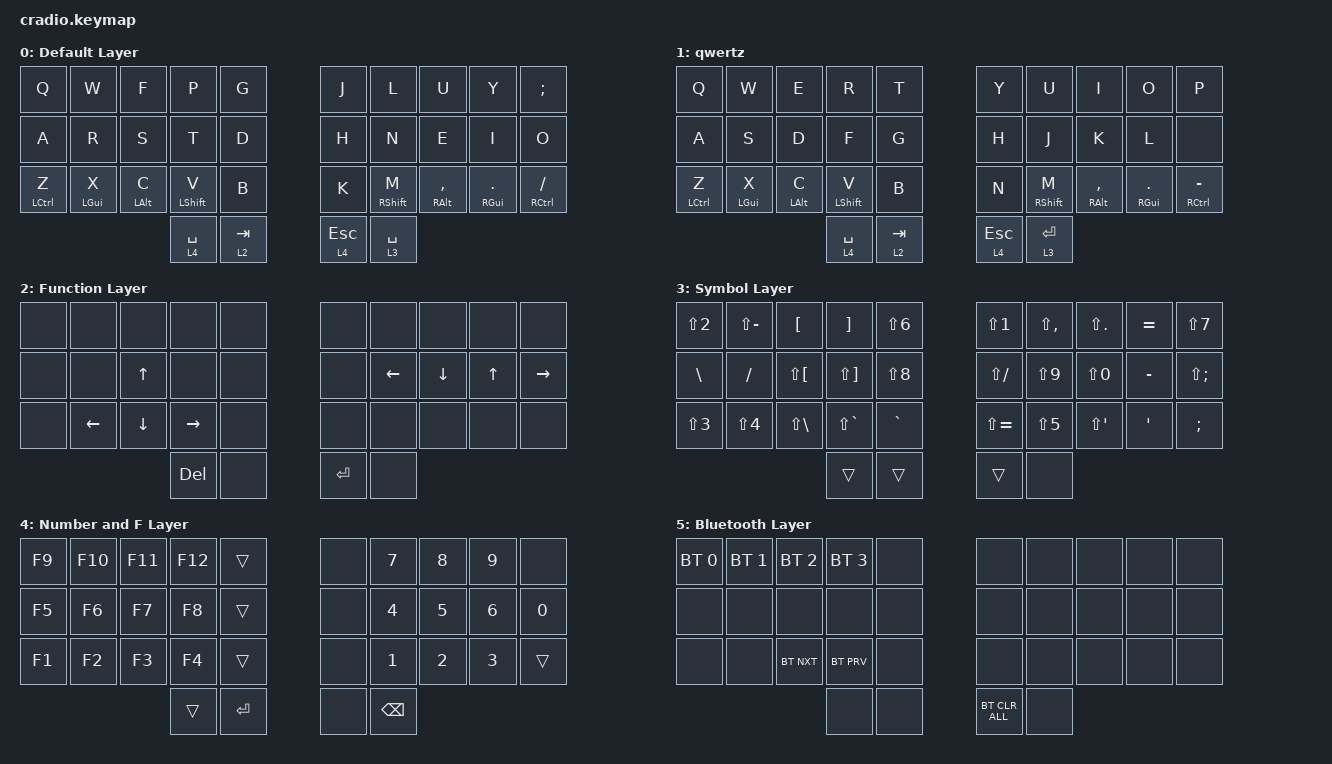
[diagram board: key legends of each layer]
// Copyright (c) 2022 The ZMK Contributors
// SPDX-License-Identifier: MIT

#include <behaviors.dtsi>
#include <dt-bindings/zmk/bt.h>
#include <dt-bindings/zmk/keys.h>

&mt {
    tapping-term-ms = <200>; // 200 = acelasi prag ca &lt (stock ZMK), consistent peste tot
    flavor = "tap-preferred";
    // roll-urile rapide (th, he) raman tap-uri; hold-ul cere 150ms de idle inainte
    require-prior-idle-ms = <150>;
};

/ {
    combos {
        compatible = "zmk,combos";

        // QWFP (stanga, top row) = toggle layer 2 (nav/arrows) — 50ms default timeout
        toggle_nav {
            bindings = <&tog 2>;
            key-positions = <0 1 2 3>;
        };

        // L U Z , (dreapta, top row, oglinda QWFP) = toggle qwertz
        toggle_qwertz {
            bindings = <&tog 1>;
            key-positions = <6 7 8 9>;
        };

        // 4 thumbs = toggle layer 5 (BT) — intrare deliberata, aproape imposibil accidental
        toggle_bt {
            bindings = <&tog 5>;
            key-positions = <30 31 32 33>;
            timeout-ms = <80>; // split 2+2 master/slave: latenta BLE mananca din fereastra de 50ms
        };
    };

    keymap {
        compatible = "zmk,keymap";

        default_layer {
            display-name = "Default Layer";
            bindings = <
&kp Q               &kp W               &kp F               &kp P               &kp G               &kp J               &kp L               &kp U               &kp Y               &kp SEMI
&kp A               &kp R               &kp S               &kp T               &kp D               &kp H               &kp N               &kp E               &kp I               &kp O
&mt LCTRL Z         &mt LGUI X          &mt LALT C          &mt LSHFT V         &kp B               &kp K               &mt RSHFT M         &mt RALT COMMA      &mt RGUI DOT        &mt RCTRL SLASH
                                         &lt 4 SPACE         &lt 2 TAB           &lt 4 ESC           &lt 3 SPACE
            >;
        };

        qwertz {
            display-name = "qwertz";
            bindings = <
&kp Q               &kp W               &kp E               &kp R               &kp T               &kp Y               &kp U               &kp I               &kp O               &kp P
&kp A               &kp S               &kp D               &kp F               &kp G               &kp H               &kp J               &kp K               &kp L               &none
&mt LCTRL Z         &mt LGUI X          &mt LALT C          &mt LSHFT V         &kp B               &kp N               &mt RSHFT M         &mt RALT COMMA      &mt RGUI DOT        &mt RCTRL MINUS
                                         &lt 4 SPACE         &lt 2 TAB           &lt 4 ESC           &lt 3 RET
            >;
        };

        function_layer {
            display-name = "Function Layer";
            bindings = <
&none               &none               &none               &none               &none               &none               &none               &none               &none               &none
&none               &none               &kp UP_ARROW        &none               &none               &none               &kp LEFT            &kp DOWN            &kp UP              &kp RIGHT
&none               &kp LEFT            &kp DOWN_ARROW      &kp RIGHT           &none               &none               &none               &none               &none               &none
                                         &kp DEL             &none               &kp RET             &none
            >;
        };

        symbol_layer {
            display-name = "Symbol Layer";
            bindings = <
&kp LS(N2)          &kp LS(MINUS)       &kp LEFT_BRACKET    &kp RIGHT_BRACKET   &kp LS(N6)          &kp LS(N1)          &kp LS(COMMA)       &kp LS(DOT)         &kp EQUAL           &kp LS(N7)
&kp BACKSLASH       &kp SLASH           &kp LS(LEFT_BRACKET)&kp LS(RIGHT_BRACKET)&kp LS(N8)          &kp LS(SLASH)       &kp LS(N9)          &kp LS(N0)          &kp MINUS           &kp LS(SEMI)
&kp LS(N3)    &kp LS(N4)          &kp LS(BACKSLASH)   &kp LS(GRAVE)       &kp GRAVE           &kp LS(EQUAL)       &kp LS(N5)          &kp LS(SINGLE_QUOTE)&kp SINGLE_QUOTE          &kp SEMI
                                         &trans              &trans              &trans              &none
            >;
        };

        nr_layer {
            display-name = "Number and F Layer";
            bindings = <
&kp F9              &kp F10             &kp F11             &kp F12             &trans              &none               &kp N7              &kp N8              &kp N9              &none
&kp F5              &kp F6              &kp F7              &kp F8              &trans              &none               &kp N4              &kp N5              &kp N6              &kp N0
&kp F1              &kp F2              &kp F3              &kp F4              &trans              &none               &kp N1              &kp N2              &kp N3              &trans
                                         &trans              &kp RET             &none               &kp BSPC
            >;
        };

        bt_layer {
            display-name = "Bluetooth Layer";
            bindings = <
&bt BT_SEL 0        &bt BT_SEL 1        &bt BT_SEL 2        &bt BT_SEL 3        &none               &none               &none               &none               &none               &none
&none               &none               &none               &none               &none               &none               &none               &none               &none               &none
&none               &none               &bt BT_NXT          &bt BT_PRV          &none               &none               &none               &none               &none               &none
                                         &none               &none               &bt BT_CLR_ALL      &none
            >;
        };
    };
};

/*
 * ---- Varianta US: ce s-a schimbat fata de branch-ul DE ----
 * Traducere output-first: fiecare binding produce pe un host en-US exact caracterul
 * pe care il producea pe host de-DE. Consecinte:
 *  - literele y/z sunt inversate fata de branch-ul DE (acolo &kp Z dadea 'y' pe QWERTZ)
 *  - stratul de simboluri e rescris pentru US: @ = LS(N2), _ = LS(MINUS),
 *    [ ] = LEFT_BRACKET/RIGHT_BRACKET, { } = LS(...), \ = BACKSLASH, | = LS(BACKSLASH),
 *    ~ = LS(GRAVE), ` = GRAVE, + = LS(EQUAL), " = LS(SINGLE_QUOTE), # = LS(N3),
 *    ? = LS(SLASH), < > = LS(COMMA)/LS(DOT), * = LS(N8)
 *  - pierdute (nu exista pe US simplu): ae/oe/ue/sz (5 pozitii) -> &none
 *
 * Umlaute pe US, daca le vrei totusi: nu exista tasta, doar input Unicode.
 * Pe Linux (Ctrl+Shift+U) si Windows (Alt+numpad) merge cu macro-uri, dar nu e
 * portabil intre sisteme, deci nu e activat. Exemplu de macro pentru Linux:
 *
 *   alt_ae: macro_ae {
 *       compatible = "zmk,behavior-macro";
 *       #binding-cells = <0>;
 *       bindings = <&kp LCTRL &kp LSHFT &kp U &kp N0 &kp N0 &kp E &kp N4 &kp RET>;
 *   };
 */
